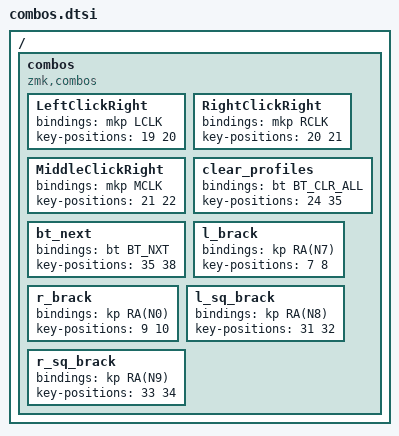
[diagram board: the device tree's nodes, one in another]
/* --- KEY ID LAYOUT --- */
// ╭──────┬──────┬──────┬──────┬──────┬──────╮  ╭──────┬──────┬──────┬──────┬──────┬──────╮
//    00     01     02     03    04      05        06     07     08     09     10     11
// ├──────┼──────┼──────┼──────┼──────┼──────┤  ├──────┼──────┼──────┼──────┼──────┼──────┤
//    12     13     14     15    16      17        18     19     20     21     22     23
// ├──────┼──────┼──────┼──────┼──────┼──────┤  ├──────┼──────┼──────┼──────┼──────┼──────┤
//    24     25     26     27    28      29        30     31     32     33     34     35
// ╰──────┴──────┴──────┼──────┼──────┼──────┤  ├──────┼──────┼──────┴──────┴──────┴──────╯
//                         36     37     38        39     40
//                      ╰──────┴──────┴──────╯  ╰──────┴──────╯

/ {
    combos {
        compatible = "zmk,combos";

        LeftClickRight {
            bindings = <&mkp LCLK>;
            key-positions = <19 20>;
        };

        RightClickRight {
            bindings = <&mkp RCLK>;
            key-positions = <20 21>;
        };

        MiddleClickRight {
            bindings = <&mkp MCLK>;
            key-positions = <21 22>;
        };

        clear_profiles {
            bindings = <&bt BT_CLR_ALL>;
            key-positions = <24 35>;
        };

        bt_next {
            bindings = <&bt BT_NXT>;
            key-positions = <35 38>;
        };

        l_brack {
            bindings = <&kp RA(N7)>;
            key-positions = <7 8>;
        };

        r_brack {
            bindings = <&kp RA(N0)>;
            key-positions = <9 10>;
        };

        l_sq_brack {
            bindings = <&kp RA(N8)>;
            key-positions = <31 32>;
        };

        r_sq_brack {
            bindings = <&kp RA(N9)>;
            key-positions = <33 34>;
        };
    };
};
